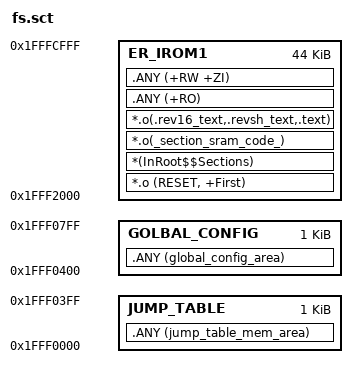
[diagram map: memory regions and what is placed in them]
; *************************************************************
; *** Scatter-Loading Description File generated by uVision ***
; *************************************************************

LR_IROM1 0x1fff2000 0x0000b000  {    ; load region size_region
  ER_IROM1 0x1fff2000 0x0000b000  {  ; load address = execution address
   *.o (RESET, +First)
   *(InRoot$$Sections)
   *.o(_section_sram_code_)
   *.o(.rev16_text,.revsh_text,.text)
   .ANY (+RO)
   .ANY (+RW +ZI)
  }
}

LR_IROM2  0x1fff0000 0x00800 {
  JUMP_TABLE 0x1fff0000 0x00400  {
   .ANY (jump_table_mem_area) 
	
  }
  GOLBAL_CONFIG 0x1fff0400 0x00400  {
   .ANY (global_config_area) 
	
  }  
} 
;LR_IROM23  0x11032000 0x10000 {
  ;ER_IROM3 0x11032000 0x10000  {
   ;gpio_demo.o (+RO)
   ;core_*.o (+RO)	
  ;}
;} 

;xip test
;0x11020000,0x1103C000
;LR_IROM3 0x11020000 0x1c000  {    ; load region size_region
  ;ER_IROM3 0x11020000 0x1c000  {  ; load address = execution address
	;fs_test.o (+RO) 
  ;}
;}

